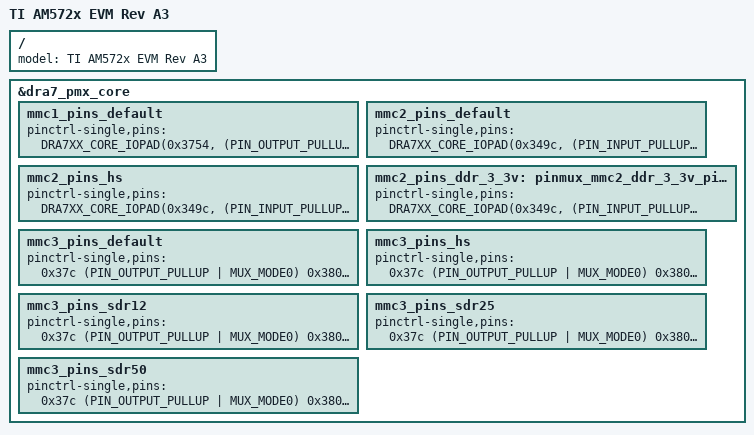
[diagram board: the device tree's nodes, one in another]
/*
 * Copyright (C) 2016 Texas Instruments Incorporated - http://www.ti.com/
 *
 * This program is free software; you can redistribute it and/or modify
 * it under the terms of the GNU General Public License version 2 as
 * published by the Free Software Foundation.
 */

#include "am57xx-beagle-x15-revc.dts"
#include "am57xx-evm-common.dtsi"
#include "am57xx-industrial-grade.dtsi"

/ {
	model = "TI AM572x EVM Rev A3";
};

&dra7_pmx_core {

	/*
	 * TODO: We should be able to move PinMux values defined here to
	 * am57xx-beagle-x15-revb1.dts once that board is available and
	 * its MMC/SD interface is verified. For now these stay here until
	 * that exercise is complete.
	 */

	mmc1_pins_default: mmc1_pins_default {
		pinctrl-single,pins = <
			DRA7XX_CORE_IOPAD(0x3754, (PIN_OUTPUT_PULLUP | MUX_MODE0)) /* mmc1_clk.clk */
			DRA7XX_CORE_IOPAD(0x3758, (PIN_INPUT_PULLUP | MUX_MODE0)) /* mmc1_cmd.cmd */
			DRA7XX_CORE_IOPAD(0x375c, (PIN_INPUT_PULLUP | MUX_MODE0)) /* mmc1_dat0.dat0 */
			DRA7XX_CORE_IOPAD(0x3760, (PIN_INPUT_PULLUP | MUX_MODE0)) /* mmc1_dat1.dat1 */
			DRA7XX_CORE_IOPAD(0x3764, (PIN_INPUT_PULLUP | MUX_MODE0)) /* mmc1_dat2.dat2 */
			DRA7XX_CORE_IOPAD(0x3768, (PIN_INPUT_PULLUP | MUX_MODE0)) /* mmc1_dat3.dat3 */
		>;
	};

	mmc2_pins_default: mmc2_pins_default {
		pinctrl-single,pins = <
			DRA7XX_CORE_IOPAD(0x349c, (PIN_INPUT_PULLUP | MUX_MODE1)) /* gpmc_a23.mmc2_clk */
			DRA7XX_CORE_IOPAD(0x34b0, (PIN_INPUT_PULLUP | MUX_MODE1)) /* gpmc_cs1.mmc2_cmd */
			DRA7XX_CORE_IOPAD(0x34a0, (PIN_INPUT_PULLUP | MUX_MODE1)) /* gpmc_a24.mmc2_dat0 */
			DRA7XX_CORE_IOPAD(0x34a4, (PIN_INPUT_PULLUP | MUX_MODE1)) /* gpmc_a25.mmc2_dat1 */
			DRA7XX_CORE_IOPAD(0x34a8, (PIN_INPUT_PULLUP | MUX_MODE1)) /* gpmc_a26.mmc2_dat2 */
			DRA7XX_CORE_IOPAD(0x34ac, (PIN_INPUT_PULLUP | MUX_MODE1)) /* gpmc_a27.mmc2_dat3 */
			DRA7XX_CORE_IOPAD(0x348c, (PIN_INPUT_PULLUP | MUX_MODE1)) /* gpmc_a19.mmc2_dat4 */
			DRA7XX_CORE_IOPAD(0x3490, (PIN_INPUT_PULLUP | MUX_MODE1)) /* gpmc_a20.mmc2_dat5 */
			DRA7XX_CORE_IOPAD(0x3494, (PIN_INPUT_PULLUP | MUX_MODE1)) /* gpmc_a21.mmc2_dat6 */
			DRA7XX_CORE_IOPAD(0x3498, (PIN_INPUT_PULLUP | MUX_MODE1)) /* gpmc_a22.mmc2_dat7 */
		>;
	};

	mmc2_pins_hs: mmc2_pins_hs {
		pinctrl-single,pins = <
			DRA7XX_CORE_IOPAD(0x349c, (PIN_INPUT_PULLUP | MUX_MODE1)) /* gpmc_a23.mmc2_clk */
			DRA7XX_CORE_IOPAD(0x34b0, (PIN_INPUT_PULLUP | MUX_MODE1)) /* gpmc_cs1.mmc2_cmd */
			DRA7XX_CORE_IOPAD(0x34a0, (PIN_INPUT_PULLUP | MUX_MODE1)) /* gpmc_a24.mmc2_dat0 */
			DRA7XX_CORE_IOPAD(0x34a4, (PIN_INPUT_PULLUP | MUX_MODE1)) /* gpmc_a25.mmc2_dat1 */
			DRA7XX_CORE_IOPAD(0x34a8, (PIN_INPUT_PULLUP | MUX_MODE1)) /* gpmc_a26.mmc2_dat2 */
			DRA7XX_CORE_IOPAD(0x34ac, (PIN_INPUT_PULLUP | MUX_MODE1)) /* gpmc_a27.mmc2_dat3 */
			DRA7XX_CORE_IOPAD(0x348c, (PIN_INPUT_PULLUP | MUX_MODE1)) /* gpmc_a19.mmc2_dat4 */
			DRA7XX_CORE_IOPAD(0x3490, (PIN_INPUT_PULLUP | MUX_MODE1)) /* gpmc_a20.mmc2_dat5 */
			DRA7XX_CORE_IOPAD(0x3494, (PIN_INPUT_PULLUP | MUX_MODE1)) /* gpmc_a21.mmc2_dat6 */
			DRA7XX_CORE_IOPAD(0x3498, (PIN_INPUT_PULLUP | MUX_MODE1)) /* gpmc_a22.mmc2_dat7 */
		>;
	};

	mmc2_pins_ddr_3_3v: pinmux_mmc2_ddr_3_3v_pins {
		pinctrl-single,pins = <
			DRA7XX_CORE_IOPAD(0x349c, (PIN_INPUT_PULLUP | MUX_MODE1)) /* gpmc_a23.mmc2_clk */
			DRA7XX_CORE_IOPAD(0x34b0, (PIN_INPUT_PULLUP | MUX_MODE1)) /* gpmc_cs1.mmc2_cmd */
			DRA7XX_CORE_IOPAD(0x34a0, (PIN_INPUT_PULLUP | MUX_MODE1)) /* gpmc_a24.mmc2_dat0 */
			DRA7XX_CORE_IOPAD(0x34a4, (PIN_INPUT_PULLUP | MUX_MODE1)) /* gpmc_a25.mmc2_dat1 */
			DRA7XX_CORE_IOPAD(0x34a8, (PIN_INPUT_PULLUP | MUX_MODE1)) /* gpmc_a26.mmc2_dat2 */
			DRA7XX_CORE_IOPAD(0x34ac, (PIN_INPUT_PULLUP | MUX_MODE1)) /* gpmc_a27.mmc2_dat3 */
			DRA7XX_CORE_IOPAD(0x348c, (PIN_INPUT_PULLUP | MUX_MODE1)) /* gpmc_a19.mmc2_dat4 */
			DRA7XX_CORE_IOPAD(0x3490, (PIN_INPUT_PULLUP | MUX_MODE1)) /* gpmc_a20.mmc2_dat5 */
			DRA7XX_CORE_IOPAD(0x3494, (PIN_INPUT_PULLUP | MUX_MODE1)) /* gpmc_a21.mmc2_dat6 */
			DRA7XX_CORE_IOPAD(0x3498, (PIN_INPUT_PULLUP | MUX_MODE1)) /* gpmc_a22.mmc2_dat7 */
		>;
	};

	mmc3_pins_default: mmc3_pins_default {
		pinctrl-single,pins = <
			0x37c (PIN_OUTPUT_PULLUP | MUX_MODE0)/* mmc3_clk.mmc3_clk */
			0x380 (PIN_INPUT_PULLUP | MUX_MODE0) /* mmc3_cmd.mmc3_cmd */
			0x384 (PIN_INPUT_PULLUP | MUX_MODE0) /* mmc3_dat0.mmc3_dat0 */
			0x388 (PIN_INPUT_PULLUP | MUX_MODE0) /* mmc3_dat1.mmc3_dat1 */
			0x38c (PIN_INPUT_PULLUP | MUX_MODE0) /* mmc3_dat2.mmc3_dat2 */
			0x390 (PIN_INPUT_PULLUP | MUX_MODE0) /* mmc3_dat3.mmc3_dat3 */
		>;
	};

	mmc3_pins_hs: mmc3_pins_hs {
		pinctrl-single,pins = <
			0x37c (PIN_OUTPUT_PULLUP | MUX_MODE0)/* mmc3_clk.mmc3_clk */
			0x380 (PIN_INPUT_PULLUP | MUX_MODE0) /* mmc3_cmd.mmc3_cmd */
			0x384 (PIN_INPUT_PULLUP | MUX_MODE0) /* mmc3_dat0.mmc3_dat0 */
			0x388 (PIN_INPUT_PULLUP | MUX_MODE0) /* mmc3_dat1.mmc3_dat1 */
			0x38c (PIN_INPUT_PULLUP | MUX_MODE0) /* mmc3_dat2.mmc3_dat2 */
			0x390 (PIN_INPUT_PULLUP | MUX_MODE0) /* mmc3_dat3.mmc3_dat3 */
		>;
	};

	mmc3_pins_sdr12: mmc3_pins_sdr12 {
		pinctrl-single,pins = <
			0x37c (PIN_OUTPUT_PULLUP | MUX_MODE0)/* mmc3_clk.mmc3_clk */
			0x380 (PIN_INPUT_PULLUP | MUX_MODE0) /* mmc3_cmd.mmc3_cmd */
			0x384 (PIN_INPUT_PULLUP | MUX_MODE0) /* mmc3_dat0.mmc3_dat0 */
			0x388 (PIN_INPUT_PULLUP | MUX_MODE0) /* mmc3_dat1.mmc3_dat1 */
			0x38c (PIN_INPUT_PULLUP | MUX_MODE0) /* mmc3_dat2.mmc3_dat2 */
			0x390 (PIN_INPUT_PULLUP | MUX_MODE0) /* mmc3_dat3.mmc3_dat3 */
		>;
	};

	mmc3_pins_sdr25: mmc3_pins_sdr25 {
		pinctrl-single,pins = <
			0x37c (PIN_OUTPUT_PULLUP | MUX_MODE0)/* mmc3_clk.mmc3_clk */
			0x380 (PIN_INPUT_PULLUP | MUX_MODE0) /* mmc3_cmd.mmc3_cmd */
			0x384 (PIN_INPUT_PULLUP | MUX_MODE0) /* mmc3_dat0.mmc3_dat0 */
			0x388 (PIN_INPUT_PULLUP | MUX_MODE0) /* mmc3_dat1.mmc3_dat1 */
			0x38c (PIN_INPUT_PULLUP | MUX_MODE0) /* mmc3_dat2.mmc3_dat2 */
			0x390 (PIN_INPUT_PULLUP | MUX_MODE0) /* mmc3_dat3.mmc3_dat3 */
		>;
	};

	mmc3_pins_sdr50: mmc3_pins_sdr50 {
		pinctrl-single,pins = <
			0x37c (PIN_OUTPUT_PULLUP | MUX_MODE0)/* mmc3_clk.mmc3_clk */
			0x380 (PIN_INPUT_PULLUP | MUX_MODE0) /* mmc3_cmd.mmc3_cmd */
			0x384 (PIN_INPUT_PULLUP | MUX_MODE0) /* mmc3_dat0.mmc3_dat0 */
			0x388 (PIN_INPUT_PULLUP | MUX_MODE0) /* mmc3_dat1.mmc3_dat1 */
			0x38c (PIN_INPUT_PULLUP | MUX_MODE0) /* mmc3_dat2.mmc3_dat2 */
			0x390 (PIN_INPUT_PULLUP | MUX_MODE0) /* mmc3_dat3.mmc3_dat3 */
		>;
	};
};
